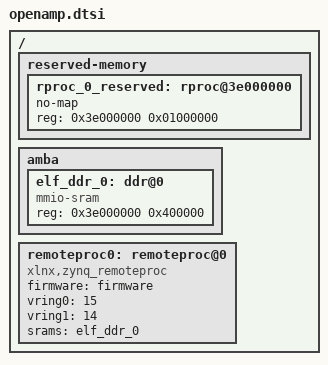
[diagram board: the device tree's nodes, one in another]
/ {
	reserved-memory {
		#address-cells = <1>;
		#size-cells = <1>;
		ranges;
		rproc_0_reserved: rproc@3e000000 {
			no-map;
			reg =  <0x3e000000 0x01000000>;
		};
	};

	amba {
		elf_ddr_0: ddr@0 {
			compatible = "mmio-sram";
			reg = <0x3e000000 0x400000>;
		};
	};
	remoteproc0: remoteproc@0 {
		compatible = "xlnx,zynq_remoteproc";
		firmware = "firmware";
		vring0 = <15>;
		vring1 = <14>;
		srams = <&elf_ddr_0>;

	};
};
